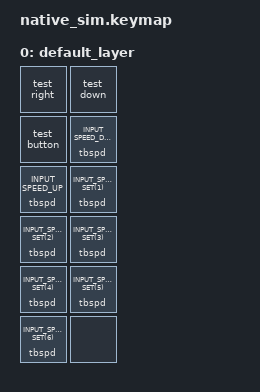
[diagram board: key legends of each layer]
#include <zephyr/dt-bindings/gpio/gpio.h>
#include <zephyr/dt-bindings/input/input-event-codes.h>

#include <behaviors.dtsi>
#include <dt-bindings/zmk/input_speed.h>
#include <dt-bindings/zmk/kscan_mock.h>

/ {
    behaviors {
        test_right: test_right {
            compatible = "zmk,behavior-gpio-emul-input";
            #binding-cells = <0>;
            gpios = <&gpio0 2 GPIO_ACTIVE_HIGH>;
        };
        test_down: test_down {
            compatible = "zmk,behavior-gpio-emul-input";
            #binding-cells = <0>;
            gpios = <&gpio0 4 GPIO_ACTIVE_HIGH>;
        };
        test_button: test_button {
            compatible = "zmk,behavior-gpio-emul-input";
            #binding-cells = <0>;
            gpios = <&gpio0 5 GPIO_ACTIVE_HIGH>;
        };
        tbspd: test_speed {
            compatible = "zmk,behavior-input-speed";
            #binding-cells = <2>;
            processor = <&trackball_speed>;
        };
    };

    trackball: trackball {
        compatible = "sparkfun,blackberry-trackballer";
        left-gpios = <&gpio0 1 GPIO_ACTIVE_HIGH>;
        right-gpios = <&gpio0 2 GPIO_ACTIVE_HIGH>;
        up-gpios = <&gpio0 3 GPIO_ACTIVE_HIGH>;
        down-gpios = <&gpio0 4 GPIO_ACTIVE_HIGH>;
        button-gpios = <&gpio0 5 GPIO_ACTIVE_HIGH>;
        zephyr,axis-x = <INPUT_REL_X>;
        zephyr,axis-y = <INPUT_REL_Y>;
        report-period-ms = <8>;
        acceleration-start-hz = <100>;
        acceleration-max-hz = <200>;
        minimum-step = <1>;
        maximum-step = <1>;
    };

    trackball_speed: trackball_speed {
        compatible = "zmk,input-processor-speed-profile";
        #input-processor-cells = <0>;
        type = <INPUT_EV_REL>;
        codes = <INPUT_REL_X INPUT_REL_Y>;
        speed-percentages = <50 100 150 200 300>;
        default-speed-level = <2>;
        track-remainders;
    };

    trackball_listener: trackball_listener {
        compatible = "zmk,input-listener";
        device = <&trackball>;
        input-processors = <&trackball_speed>;
    };

    keymap {
        compatible = "zmk,keymap";

        default_layer {
            bindings = <
                &test_right                 &test_down
                &test_button                &tbspd INPUT_SPEED_DOWN
                &tbspd INPUT_SPEED_UP       &tbspd INPUT_SPEED_SET(1)
                &tbspd INPUT_SPEED_SET(2)   &tbspd INPUT_SPEED_SET(3)
                &tbspd INPUT_SPEED_SET(4)   &tbspd INPUT_SPEED_SET(5)
                &tbspd INPUT_SPEED_SET(6)   &none
            >;
        };
    };
};

&kscan {
    rows = <3>;
    columns = <4>;
    events = <
        /* Default level 2 is 100%. */
        ZMK_MOCK_PRESS(0,0,1)
        ZMK_MOCK_RELEASE(0,0,20)

        /* Relative DOWN/UP commands are clamped absolute changes on central. */
        ZMK_MOCK_PRESS(0,3,1)
        ZMK_MOCK_RELEASE(0,3,1)
        ZMK_MOCK_PRESS(0,0,1)
        ZMK_MOCK_RELEASE(0,0,20)
        ZMK_MOCK_PRESS(1,0,1)
        ZMK_MOCK_RELEASE(1,0,1)

        /* Directly select every level. */
        ZMK_MOCK_PRESS(1,1,1)
        ZMK_MOCK_RELEASE(1,1,1)
        ZMK_MOCK_PRESS(0,1,1)
        ZMK_MOCK_RELEASE(0,1,20)
        ZMK_MOCK_PRESS(1,2,1)
        ZMK_MOCK_RELEASE(1,2,1)
        ZMK_MOCK_PRESS(0,0,1)
        ZMK_MOCK_RELEASE(0,0,20)
        ZMK_MOCK_PRESS(1,3,1)
        ZMK_MOCK_RELEASE(1,3,1)
        ZMK_MOCK_PRESS(0,0,1)
        ZMK_MOCK_RELEASE(0,0,20)
        ZMK_MOCK_PRESS(0,0,1)
        ZMK_MOCK_RELEASE(0,0,20)
        ZMK_MOCK_PRESS(2,0,1)
        ZMK_MOCK_RELEASE(2,0,1)
        ZMK_MOCK_PRESS(0,0,1)
        ZMK_MOCK_RELEASE(0,0,20)
        ZMK_MOCK_PRESS(2,1,1)
        ZMK_MOCK_RELEASE(2,1,1)
        ZMK_MOCK_PRESS(0,0,1)
        ZMK_MOCK_RELEASE(0,0,20)

        /* UP at level 5 does not wrap; an invalid SET leaves it unchanged. */
        ZMK_MOCK_PRESS(1,0,1)
        ZMK_MOCK_RELEASE(1,0,1)
        ZMK_MOCK_PRESS(0,0,1)
        ZMK_MOCK_RELEASE(0,0,20)
        ZMK_MOCK_PRESS(2,2,1)
        ZMK_MOCK_RELEASE(2,2,1)
        ZMK_MOCK_PRESS(0,0,1)
        ZMK_MOCK_RELEASE(0,0,20)

        /* DOWN at level 1 does not wrap. */
        ZMK_MOCK_PRESS(1,1,1)
        ZMK_MOCK_RELEASE(1,1,1)
        ZMK_MOCK_PRESS(0,3,1)
        ZMK_MOCK_RELEASE(0,3,1)

        /* X and Y keep independent 50% remainders. */
        ZMK_MOCK_PRESS(0,0,1)
        ZMK_MOCK_RELEASE(0,0,20)
        ZMK_MOCK_PRESS(0,1,1)
        ZMK_MOCK_RELEASE(0,1,20)
        ZMK_MOCK_PRESS(0,0,1)
        ZMK_MOCK_RELEASE(0,0,20)
        ZMK_MOCK_PRESS(0,1,1)
        ZMK_MOCK_RELEASE(0,1,20)
        ZMK_MOCK_PRESS(0,0,1)
        ZMK_MOCK_RELEASE(0,0,20)
        ZMK_MOCK_PRESS(0,1,1)
        ZMK_MOCK_RELEASE(0,1,20)

        /* A non-X/Y button event passes through unchanged. */
        ZMK_MOCK_PRESS(0,2,10)
        ZMK_MOCK_RELEASE(0,2,20)
    >;
};
